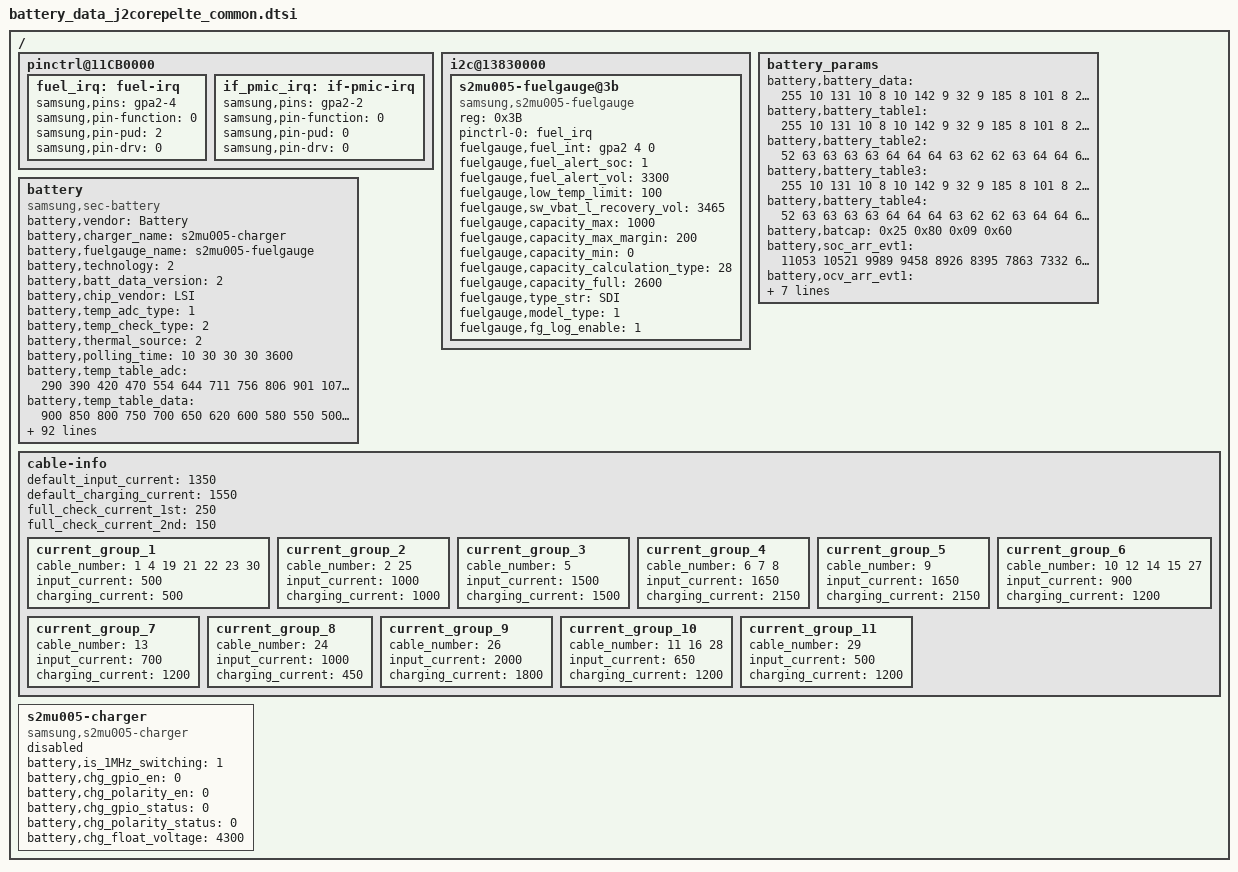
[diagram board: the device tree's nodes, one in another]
/*
 * J2 CORE Battery parameters device tree file for board IDs 00 and higher
 *
 * Copyright (C) 2017 Samsung Electronics, Inc.
 *
 * This program is free software; you can redistribute it and/or
 * modify it under the terms of the GNU General Public License
 * as published by the Free Software Foundation; either version 2
 * of the License, or (at your option) any later version.
 *
 * This program is distributed in the hope that it will be useful,
 * but WITHOUT ANY WARRANTY; without even the implied warranty of
 * MERCHANTABILITY or FITNESS FOR A PARTICULAR PURPOSE.  See the
 * GNU General Public License for more details.
 *
 * You should have received a copy of the GNU General Public License
 * along with this program. If not, see <http://www.gnu.org/licenses/>.
 *
 */

/ {
	pinctrl@11CB0000 {
		fuel_irq: fuel-irq {
			samsung,pins = "gpa2-4";
			samsung,pin-function = <0>;
			samsung,pin-pud = <2>;
			samsung,pin-drv = <0>;
		};

		if_pmic_irq: if-pmic-irq {
			samsung,pins = "gpa2-2";
			samsung,pin-function = <0>;
			samsung,pin-pud = <0>;
			samsung,pin-drv = <0>;
		};
	};

	i2c@13830000 {
		status = "okay";
		s2mu005-fuelgauge@3b {
			compatible = "samsung,s2mu005-fuelgauge";
			reg = <0x3B>;
			pinctrl-names = "default";
			pinctrl-0 = <&fuel_irq>;
			fuelgauge,fuel_int = <&gpa2 4 0>;
			fuelgauge,fuel_alert_soc = <1>;
			fuelgauge,fuel_alert_vol = <3300>;
			fuelgauge,low_temp_limit = <100>;
			fuelgauge,sw_vbat_l_recovery_vol = <3465>;
			fuelgauge,capacity_max = <1000>;
			fuelgauge,capacity_max_margin = <200>;
			fuelgauge,capacity_min = <0>;
			fuelgauge,capacity_calculation_type = <28>;
			fuelgauge,capacity_full = <2600>;
			fuelgauge,type_str = "SDI";
			fuelgauge,model_type = <1>;
			fuelgauge,fg_log_enable = <1>;
		};
	};

	battery_params {
			battery,battery_data =
			<
				/***** battery data for 4.30 *****/
				/* battery,battery_table3 */
				255 10 131 10 8 10 142 9 32 9
				185 8 101 8 218 7 169 7 98 7
				14 7 184 6 135 6 101 6 75 6
				56 6 39 6 2 6 194 5 138 5
				11 5 249 1 216 8 107 8 254 7
				145 7 36 7 183 6 74 6 222 5
				113 5 4 5 151 4 42 4 189 3
				80 3 228 2 119 2 10 2 157 1
				48 1 195 0 86 0 234 15

				/* battery,battery_table4 */
				52 63 63 63 63 64 64 64 63 62
				62 63 64 64 65 65 66 68 71 81
				104 104

				/* battery,batcap */
				0x27 0x60 0x09 0xD8 /* [0x0F] [0x0E] [0x11] [0x10] */
				/* battery,accum */
				0x00 0x8 /* [0x44] [0x45] */

				/* battery,soc_arr_val */
				11053 10521 9989 9458 8926 8395 7863 7332 6800 6269
				5737 5205 4674 4142 3610 3079 2548 2016 1485 953
				422 (-110)
				/* battery,ocv_arr_val */
				43743 43141 42539 41942 41407 40903 40491 39814 39576 39229
				38818 38398 38161 37995 37867 37776 37692 37508 37195 36925
				36302 32467

				/***** battery data for 4.28 *****/
				/* battery,battery_table3 */
				255 10 131 10 8 10 142 9 32 9
				185 8 101 8 218 7 169 7 98 7
				14 7 184 6 135 6 101 6 75 6
				56 6 39 6 2 6 194 5 138 5
				11 5 249 1 216 8 107 8 254 7
				145 7 36 7 183 6 74 6 222 5
				113 5 4 5 151 4 42 4 189 3
				80 3 228 2 119 2 10 2 157 1
				48 1 195 0 86 0 234 15

				/* battery,battery_table4 */
				63 63 63 63 63 64 64 64 63 62
				62 63 64 64 65 65 66 68 71 81
				104 233

				/* battery,batcap */
				0x27 0x9C 0x09 0xE7 /* [0x0F] [0x0E] [0x11] [0x10] */
				/* battery,accum */
				0x00 0x8 /* [0x44] [0x45] */

				/* battery,soc_arr_val */
				11053 10521 9989 9458 8926 8395 7863 7332 6800 6269
				5737 5205 4674 4142 3610 3079 2548 2016 1485 953
				422 (-110)
				/* battery,ocv_arr_val */
				43743 43141 42539 41942 41407 40903 40491 39814 39576 39229
				38818 38398 38161 37995 37867 37776 37692 37508 37195 36925
				36302 32467

				/***** battery data for 4.26 *****/
				/* battery,battery_table3 */
				255 10 131 10 8 10 142 9 32 9
				185 8 101 8 218 7 169 7 98 7
				14 7 184 6 135 6 101 6 75 6
				56 6 39 6 2 6 194 5 138 5
				11 5 249 1 6 9 151 8 40 8
				184 7 73 7 218 6 107 6 252 5
				141 5 30 5 175 4 64 4 209 3
				98 3 243 2 131 2 20 2 165 1
				54 1 199 0 88 0 233 15

				/* battery,battery_table4 */
				63 63 63 63 63 64 64 64 63 62
				62 63 64 64 65 65 66 68 71 81
				104 233

				/* battery,batcap */
				0x26 0xAC 0x09 0xAB /* [0x0F] [0x0E] [0x11] [0x10] */
				/* battery,accum */
				0x00 0x8 /* [0x44] [0x45] */

				/* battery,soc_arr_val */
				11278 10736 10194 9651 9109 8566 8024 7482 6939 6397
				5854 5312 4770 4227 3685 3142 2600 2058 1515 973
				429 (-112)
				/* battery,ocv_arr_val */
				43743 43141 42539 41942 41407 40903 40491 39814 39576 39229
				38819 38397 38161 37995 37867 37776 37692 37508 37195 36925
				36302 32467
			>;

			battery,battery_table1 = <
					255 10 131 10 8 10 142 9 32 9
					185 8 101 8 218 7 169 7 98 7
					14 7 184 6 135 6 101 6 75 6
					56 6 39 6 2 6 194 5 138 5
					11 5 249 1 216 8 107 8 254 7
					145 7 36 7 183 6 74 6 222 5
					113 5 4 5 151 4 42 4 189 3
					80 3 228 2 119 2 10 2 157 1
					48 1 195 0 86 0 234 15
					>;

			battery,battery_table2 = <
					52 63 63 63 63 64 64 64 63 62
					62 63 64 64 65 65 66 68 71 81
					104 104
					>;

			battery,battery_table3 = <
					255 10 131 10 8 10 142 9 32 9
					185 8 101 8 218 7 169 7 98 7
					14 7 184 6 135 6 101 6 75 6
					56 6 39 6 2 6 194 5 138 5
					11 5 249 1 216 8 107 8 254 7
					145 7 36 7 183 6 74 6 222 5
					113 5 4 5 151 4 42 4 189 3
					80 3 228 2 119 2 10 2 157 1
					48 1 195 0 86 0 234 15
					>;

			battery,battery_table4 = <
					52 63 63 63 63 64 64 64 63 62
					62 63 64 64 65 65 66 68 71 81
					104 104
					>;

			battery,batcap = <0x25 0x80 0x09 0x60>; /* [0x0F] [0x0E] [0x11] [0x10] */

			battery,soc_arr_evt1 = <
						11053 10521 9989 9458 8926 8395 7863 7332 6800 6269
						5737 5205 4674 4142 3610 3079 2548 2016 1485 953
						422 (-110)
						>;
			battery,ocv_arr_evt1 = <
						43743 43141 42539 41942 41407 40903 40491 39814 39576 39229
						38818 38398 38161 37995 37867 37776 37692 37508 37195 36925
						36302 32467
						>;

			battery,soc_arr_evt2 = <
						11053 10521 9989 9458 8926 8395 7863 7332 6800 6269
						5737 5205 4674 4142 3610 3079 2548 2016 1485 953
						422 (-110)
						>;
			battery,ocv_arr_evt2 = <
						43743 43141 42539 41942 41407 40903 40491 39814 39576 39229
						38818 38398 38161 37995 37867 37776 37692 37508 37195 36925
						36302 32467
						>;

			battery,FG_Accumulative_rate_evt2 = <0x00 0x8>; /* 0x44 0x45 */
			battery,data_ver = <0x01>;
	};

	battery {
		status = "okay";
		compatible = "samsung,sec-battery";

		pinctrl-names = "default";

		battery,vendor = "Battery";
		battery,charger_name = "s2mu005-charger";
		battery,fuelgauge_name = "s2mu005-fuelgauge";
		battery,technology = <2>; /* POWER_SUPPLY_TECHNOLOGY_LION */

		battery,batt_data_version = <2>;

		battery,chip_vendor = "LSI";
		battery,temp_adc_type = <1>; /* SEC_BATTERY_ADC_TYPE_AP */

		battery,temp_check_type = <2>; /* SEC_BATTERY_TEMP_CHECK_TEMP */

		battery,thermal_source = <2>; /* SEC_BATTERY_THERMAL_SOURCE_ADC */

		battery,polling_time = <10 30 30 30 3600>;

		battery,temp_table_adc = <
					290 390 420 470 554 644 711 756 806 901
					1073 1171 1244 1318 1384 1504 1549 1579 1631 1844
    				2064 2283 2503 2707 2712 2794 2915 2986 3062 3288
    				3470 3540 3677
				>;
		battery,temp_table_data = <
					900 850 800 750 700 650 620 600 580 550
					500 470 450 430 410 400 380 360 350 300
   	 				250 200 150	130 100 80 50 30 0 (-50)
    				(-100) (-150) (-200)
				>;

		battery,inbat_voltage = <1>;

		battery,inbat_voltage_table_adc = <
						2766 2755 2728 2698 2678 2649 2620 2598 2562 2532
						2508 2475 2448 2429 2401 2370 2348 2318 2288 2258
						>;
		battery,inbat_voltage_table_data = <
						4350 4300 4250 4200 4150 4100 4050 4000 3950 3900
						3850 3800 3750 3700 3650 3600 3550 3500 3450 3400
						>;

		battery,adc_check_count = <5>;

		battery,cable_check_type = <4>; /* SEC_BATTERY_CABLE_CHECK_PSY */
		battery,cable_source_type = <1>; /* SEC_BATTERY_CABLE_SOURCE_EXTERNAL */
		battery,polling_type = <1>; /* SEC_BATTERY_MONITOR_ALARM */
		battery,monitor_initial_count = <0>;

		battery,pre_afc_input_current = <500>;

		battery,battery_check_type = <5>; /* SEC_BATTERY_CHECK_CHARGER */
		battery,check_count = <0>;
		battery,check_adc_max = <1400>;
		battery,check_adc_min = <700>;

		battery,ovp_uvlo_check_type = <3>; /* SEC_BATTERY_OVP_UVLO_CHGPOLLING */

		battery,temp_check_count = <1>;
		battery,temp_highlimit_threshold_event = <800>;
		battery,temp_highlimit_recovery_event = <750>;
		battery,temp_high_threshold_event = <500>;
		battery,temp_high_recovery_event = <450>;
		battery,temp_low_threshold_event = <0>;
		battery,temp_low_recovery_event = <50>;
		battery,temp_highlimit_threshold_normal = <800>;
		battery,temp_highlimit_recovery_normal = <750>;
		battery,temp_high_threshold_normal = <500>;
		battery,temp_high_recovery_normal = <450>;
		battery,temp_low_threshold_normal = <0>;
		battery,temp_low_recovery_normal = <50>;
		battery,temp_highlimit_threshold_lpm = <800>;
		battery,temp_highlimit_recovery_lpm = <750>;
		battery,temp_high_threshold_lpm = <500>;
		battery,temp_high_recovery_lpm = <450>;
		battery,temp_low_threshold_lpm = <0>;
		battery,temp_low_recovery_lpm = <50>;
		battery,wpc_high_threshold_normal = <450>;
		battery,wpc_high_recovery_normal = <400>;
		battery,wpc_low_threshold_normal = <0>;
		battery,wpc_low_recovery_normal = <50>;

		battery,full_check_type = <2>; /* SEC_BATTERY_FULLCHARGED_FG_CURRENT */
		battery,full_check_type_2nd = <2>; /* SEC_BATTERY_FULLCHARGED_FG_CURRENT */
		battery,full_check_count = <1>;
		battery,chg_gpio_full_check = <0>;
		battery,chg_polarity_full_check = <1>;

		/* SEC_BATTERY_FULL_CONDITION_SOC |
		   SEC_BATTERY_FULL_CONDITION_NOTIMEFULL |
		   SEC_BATTERY_FULL_CONDITION_VCELL */
		battery,full_condition_type = <13>;
		battery,full_condition_soc = <93>;
		battery,full_condition_vcell = <4250>;

		battery,recharge_check_count = <1>;
		battery,recharge_condition_type = <4>; /* SEC_BATTERY_RECHARGE_CONDITION_VCELL */
		battery,recharge_condition_soc = <98>;
		battery,recharge_condition_vcell = <4200>;

		battery,charging_total_time = <14400>;
		battery,hv_charging_total_time = <10800>;
		battery,normal_charging_total_time = <18000>;
		battery,usb_charging_total_time = <36000>;
		battery,recharging_total_time = <5400>;
		battery,charging_reset_time = <0>;

		battery,chg_float_voltage = <4300>;

		battery,swelling_high_temp_block = <410>;
		battery,swelling_high_temp_recov = <390>;
		battery,swelling_wc_high_temp_recov = <390>;
		battery,swelling_low_temp_block_1st = <150>;
		battery,swelling_low_temp_recov_1st = <200>;
		battery,swelling_low_temp_block_2nd = <50>;
		battery,swelling_low_temp_recov_2nd = <100>;

		battery,swelling_low_temp_current = <600>;	/* 0.3C */
		battery,swelling_low_temp_topoff = <150>;	/* 0.05C */
		battery,swelling_high_temp_current = <900>;	/* 0.45C */
		battery,swelling_high_temp_topoff = <150>;	/* 0.05C */
		battery,swelling_wc_high_temp_current = <600>;	/* 0.3C */
		battery,swelling_wc_low_temp_current = <600>;	/* 0.3C */

		battery,swelling_drop_float_voltage = <4100>;
		battery,swelling_high_rechg_voltage = <3950>;
		battery,swelling_low_rechg_voltage = <3950>;

		battery,siop_event_check_type = <1>;
		battery,siop_call_cv_current = <330>;
		battery,siop_call_cc_current = <330>;

		battery,siop_input_limit_current = <1200>;
		battery,siop_charging_limit_current = <1000>;
		battery,minimum_charging_current_by_siop_0 = <100>; /* if siop level is 0, set minimum charging current */
		battery,charging_current_browsing_mode = <600>; /* Set charging current in Browsing mode */

		battery,battery_full_capacity = <2600>;

		/* cycle(week), chg_float_voltage, recharge_condition_vcell, full_condition_vcell, full_condition_soc*/
		battery,age_data = <0 4300 4200 4200 93
				28 4280 4180 4180 91
				36 4260 4160 4160 90>;

		battery,standard_curr = <1550>;
		battery,expired_time = <12600>; /* 150 + 60 minutes */
		battery,recharging_expired_time = <5400>;

		battery,cisd_max_voltage_thr = <5000>; /* battery ovp detection voltage */

		battery,recovery_cable;

		io-channels = <&exynos_adc 1>, <&exynos_adc 2>;
		io-channel-names = "adc-temp", "adc-in-bat";
		#io-channel-cells = <5>;
		io-channel-ranges;
	};

	cable-info {
		default_input_current = <1350>;
		default_charging_current = <1550>;
		full_check_current_1st = <250>;
		full_check_current_2nd = <150>;

		current_group_1 {
			cable_number = <1 4 19 21 22 23 30>;
			input_current = <500>;
			charging_current = <500>;
		};

		current_group_2 {
			cable_number = <2 25>;
			input_current = <1000>;
			charging_current = <1000>;
		};

		current_group_3 {
			cable_number = <5>;
			input_current = <1500>;
			charging_current = <1500>;
		};

		current_group_4 {
			cable_number = <6 7 8>;
			input_current = <1650>;
			charging_current = <2150>;
		};

		current_group_5 {
			cable_number = <9>;
			input_current = <1650>;
			charging_current = <2150>;
		};

		current_group_6 {
			cable_number = <10 12 14 15 27>;
			input_current = <900>;
			charging_current = <1200>;
		};

		current_group_7 {
			cable_number = <13>;
			input_current = <700>;
			charging_current = <1200>;
		};

		current_group_8 {
			cable_number = <24>;
			input_current = <1000>;
			charging_current = <450>;
		};

		current_group_9 {
			cable_number = <26>;
			input_current = <2000>;
			charging_current = <1800>;
		};

		current_group_10 {
			cable_number = <11 16 28>;
			input_current = <650>;
			charging_current = <1200>;
		};

		current_group_11 {
			cable_number = <29>;
			input_current = <500>;
			charging_current = <1200>;
		};
	};

	s2mu005-charger {
		status = "disable";
		compatible = "samsung,s2mu005-charger";
		battery,is_1MHz_switching = <1>;
		battery,chg_gpio_en = <0>;
		battery,chg_polarity_en = <0>;
		battery,chg_gpio_status = <0>;
		battery,chg_polarity_status = <0>;
		battery,chg_float_voltage = <4300>;
	};
};
